# SAM9X75D2GN4 device description
Architecture: ARM926EJ-S; Family: SAM9; Series: SAM9X7
Registers are 32-bit, read-write, reset 0x0 unless marked. A register's access mark holds for its fields unless they carry their own. Offsets are from the block's base; [hi:lo] are bit positions; {n}, {i} and the like mark numbered series.

## BSC — Boot Sequence Controller
Instances: BSC 0xFFFFFE54
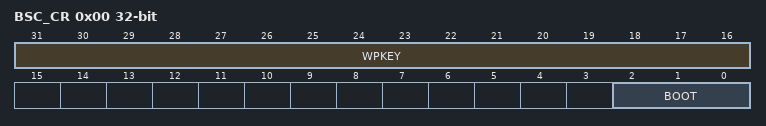
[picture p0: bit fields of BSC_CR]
0x00 BSC_CR reset not defined — Boot Sequence Controller Configuration Register
  [31:16] WPKEY — Write Protection Key (Write-only)
    0x6683=PASSWD (Writing any other value in this field aborts the write operation of the BOOT field. Always reads as 0.)
  [2:0] BOOT — Boot Media Sequence

## GPBR — General Purpose Backup Registers
Instances: GPBR 0xFFFFFE60
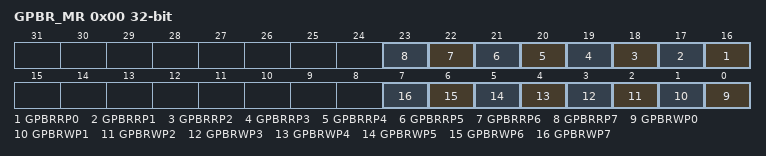
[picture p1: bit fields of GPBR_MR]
0x00 GPBR_MR — GPBR Mode Register
  [n+16] GPBRRP{n} (n=0..7) — GPBRx Read Protection
    0=The content of the corresponding GPBR register (32-bit part-select) can be read; 1=The corresponding GPBR register (32-bit part-select) always returns zero when read
  [n] GPBRWP{n} (n=0..7) — GPBRx Write Protection
    0=The corresponding GPBR register (32-bit part-select) can be written; 1=The corresponding GPBR register (32-bit part-select) is write-protected
0x04 GPBR_FCLR (atomic clear) — GPBR Full Clear Register
  [0] FCLR — Full Clear Enable
    0=SYS_GPBR0 to SYS_GPBR3 are immediately cleared in case of fast wake-up pin tamper event; 1=All SYS_GPBRx are immediately cleared in case of fast wake-up pin tamper event
{0x8+4i} SYS_GPBR[{i}] (i=0..7) — General Purpose Backup Register x
  [31:0] GPBR_VALUE — Value of SYS_GPBRx

## LVDSC — LVDS Controller
Instances: LVDSC 0xF8060000
0x00 LVDSC_CR wo — Control Register
  [0] SER_EN — LVDS Serializer Enable
    0=Disables the serializer of the LVDS; 1=Enables the serializer of the LVDS
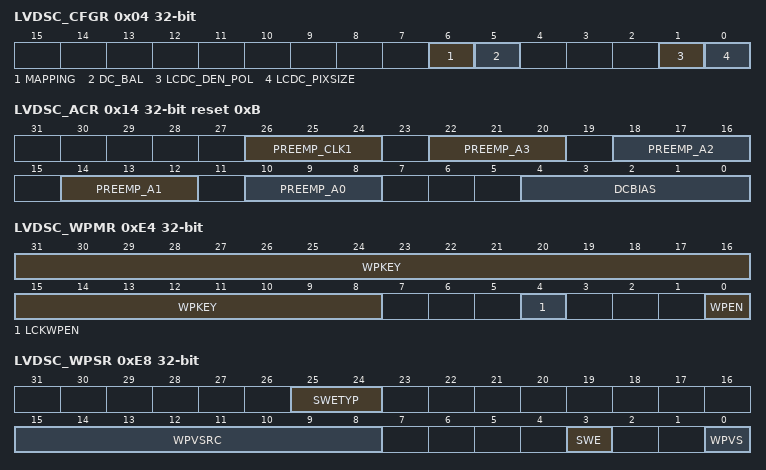
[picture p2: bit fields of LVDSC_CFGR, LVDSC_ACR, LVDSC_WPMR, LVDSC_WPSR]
0x04 LVDSC_CFGR — Configuration Register
  [6] MAPPING — LVDS mapping format (unbalanced mode only)
    0=VESA (Maps LVDS lanes to VESA format); 1=JEIDA (Maps LVDS lanes to JEIDA format)
  [5] DC_BAL — DC Mode
    0=UNBALANCED (LVDS lane is DC-unbalanced); 1=BALANCED (LVDS lane is DC-balanced)
  [1] LCDC_DEN_POL — LCDC Controller Data Enable Polarity
    0=HIGH (LCD_DEN input is active high); 1=LOW (LCD_DEN input is active low)
  [0] LCDC_PIXSIZE — LCD Controller Pixel Size
    0=24BITS (LCD controller provides 24 bits per pixel.); 1=18BITS (LCD controller provides 18 bits per pixel.)
0x08 LVDSC_UCBR — User Control Bits Register
  [2] RESA3 — Lane A3 Reserved Bit Value
    0=Asserts a logical 0 on lane A3 reserved bit location; 1=Asserts a logical 1 on lane A3 reserved bit location
0x0C LVDSC_SR ro — Status Register
  [0] CS — Configuration Status
    0=The LVDSC_CFGRand LVDSC_UCBR registers can be modified; 1=The LVDSC_CFGRand LVDSC_UCBRregistersmust not be modified
0x14 LVDSC_ACR reset 0xB — Analog Control Register
  [26:24] PREEMP_CLK1 — Pre-Emphasis Control for CLK LVDS Lane
  [4n+10:4n+8] PREEMP_A{n} (n=0..3) — Pre-Emphasis Control for Ax LVDS Lane
  [4:0] DCBIAS — Common DC Bias Control for LVDS Lanes
0xE4 LVDSC_WPMR — Write Protection Mode Register
  [31:8] WPKEY — Write Protection Key
    0x4C5644=PASSWD (Writing any other value in this field aborts the write operation of the WPEN bit. Always reads as 0.)
  [4] LCKWPEN — Lock Write Protection Enable Until Next System Reset
    0=No effect; 1=Locks the WPEN bit to 1 until the next system reset if on the same access WPEN=1 and WPKEY corresponds to 0x4C5644 ("LVD" in ASCII)
  [0] WPEN — Write Protection Enable
    0=Disables write protection if WPKEY corresponds to 0x4C5644 ("LVD" in ASCII); 1=Enables write protection if WPKEY corresponds to 0x4C5644 ("LVD" in ASCII)
0xE8 LVDSC_WPSR ro — Write Protection Status Register
  [25:24] SWETYP — Software Error Type (cleared on read)
    1=WRITE_RO (LVDSC is enabled and a write access has been performed on a read-only register.); 2=UNDEF_RW (Access to an undefined address.); 3=WEIRD_ACTION (Tentative to modify the LVDSC_CFGR when LVDSC_CR.SER_EN=1.)
  [15:8] WPVSRC — Write Protection Violation Source
  [3] SWE — Software Control Error (cleared on read)
    0=No software error has occurred since the last read of LVDSC_WPSR; 1=A software error has occurred since the last read of LVDSC_WPSR. The field SWETYP details the type of software error; the associated incorrect software access is reported in the field WPVSRC (if WPVS=0).
  [0] WPVS — Write Protection Violation Status (cleared on read)
    0=No write protect violation has occurred since the last read of LVDSC_WPSR; 1=A write protect violation has occurred since the last read of LVDSC_WPSR. The address offset of the violated register is reported into field WPVSRC.
